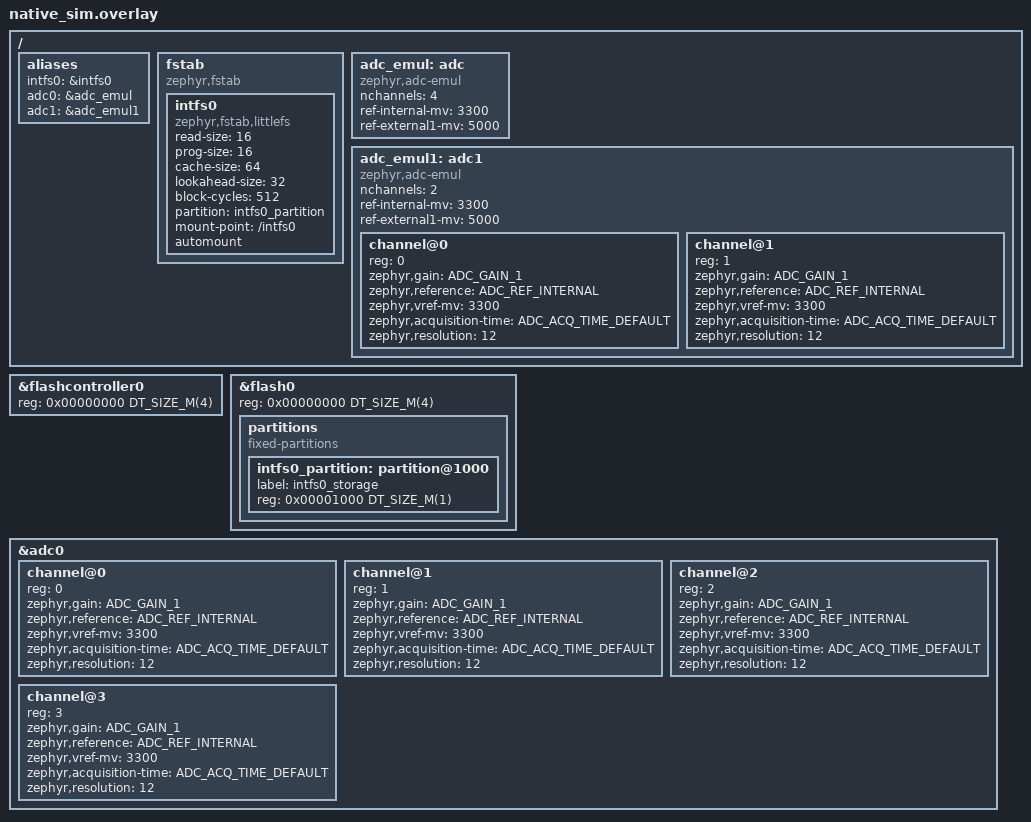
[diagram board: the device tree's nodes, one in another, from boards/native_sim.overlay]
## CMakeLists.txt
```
cmake_minimum_required(VERSION 3.20.0)

set(RT_CORE_TEST_SIM_FLASH ON)
set(RT_CORE_TEST_ADC_EMUL ON)
include(${CMAKE_CURRENT_SOURCE_DIR}/../../../rt_core_test.cmake)

find_package(Zephyr REQUIRED HINTS $ENV{ZEPHYR_BASE})
project(functional_adc_domain)

file(GLOB_RECURSE TEST_SOURCES src/*.c src/*.cpp)

target_sources(app PRIVATE ${TEST_SOURCES})

# With CONFIG_EERIE_LEAP_SMP the test client injects requests with smp_rx_req().
target_include_directories(app PRIVATE
  ${RT_CORE_DIR}/tests/common
  ${ZEPHYR_BASE}/subsys/mgmt/mcumgr/transport/include
)
```

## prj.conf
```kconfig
CONFIG_ZTEST=y

# Language and Compiler
CONFIG_CPP=y
CONFIG_PICOLIBC=y
CONFIG_STD_CPP23=y
CONFIG_REQUIRES_FULL_LIBCPP=y
CONFIG_CPP_EXCEPTIONS=y
CONFIG_CPP_RTTI=y

# Memory
CONFIG_HEAP_MEM_POOL_SIZE=100000

# C++ exception unwinding needs considerably more stack than the ztest defaults.
CONFIG_MAIN_STACK_SIZE=8192
CONFIG_ZTEST_STACK_SIZE=8192

# Logging And Debugging
CONFIG_LOG=y
CONFIG_TEST_RANDOM_GENERATOR=y
CONFIG_THREAD_ANALYZER=y
CONFIG_THREAD_ANALYZER_USE_LOG=y
CONFIG_THREAD_NAME=y
CONFIG_SYS_HEAP_RUNTIME_STATS=y
CONFIG_THREAD_ANALYZER_ISR_STACK_USAGE=n
CONFIG_TIMING_FUNCTIONS=y
CONFIG_CRC=y

# ThreadBase::InitializeStack() falls back to k_thread_stack_alloc().
CONFIG_THREAD_STACK_INFO=y
CONFIG_DYNAMIC_THREAD=y
CONFIG_DYNAMIC_THREAD_ALLOC=y

# FS Config
CONFIG_FLASH=y
CONFIG_FLASH_MAP=y
CONFIG_FILE_SYSTEM=y
CONFIG_FILE_SYSTEM_LITTLEFS=y
CONFIG_FILE_SYSTEM_MKFS=y

CONFIG_ZCBOR=y

# Hardware
CONFIG_ADC=y

CONFIG_EERIE_LEAP_RT_CORE=y
CONFIG_EERIE_LEAP_CONFIGURATION=y
CONFIG_EERIE_LEAP_ADC=y
CONFIG_EERIE_LEAP_DEVICE_TREE=y
CONFIG_EERIE_LEAP_FS=y
CONFIG_EERIE_LEAP_THREADING=y
# The calibration tests stamp their results with the time service.
CONFIG_EERIE_LEAP_TIME=y

CONFIG_EERIE_LEAP_DOMAIN_ADC=y

CONFIG_EERIE_LEAP_CONTROLLER_ADC=y
```

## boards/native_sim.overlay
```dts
/ {
	aliases {
		intfs0 = &intfs0;
		adc0 = &adc_emul;
		adc1 = &adc_emul1;
	};

	fstab {
		compatible = "zephyr,fstab";
		intfs0: intfs0 {
			compatible = "zephyr,fstab,littlefs";
			read-size = <16>;
			prog-size = <16>;
			cache-size = <64>;
			lookahead-size = <32>;
			block-cycles = <512>;
			partition = <&intfs0_partition>;
			mount-point = "/intfs0";
			automount;
		};
	};

	adc_emul: adc {
		compatible = "zephyr,adc-emul";
		nchannels = <4>;
		ref-internal-mv = <3300>;
		ref-external1-mv = <5000>;
		#io-channel-cells = <1>;
		status = "okay";
	};

	adc_emul1: adc1 {
		compatible = "zephyr,adc-emul";
		nchannels = <2>;
		ref-internal-mv = <3300>;
		ref-external1-mv = <5000>;
		#io-channel-cells = <1>;
		status = "okay";
	};
};

&flashcontroller0 {
	reg = <0x00000000 DT_SIZE_M(4)>;  // 4MB flash controller
};

// HEX Flash dump can be found in the duild/flash.bin file
&flash0 {
	reg = <0x00000000 DT_SIZE_M(4)>;  // 4MB total flash

	partitions {
		compatible = "fixed-partitions";
		#address-cells = <1>;
		#size-cells = <1>;

		intfs0_partition: partition@1000 {
			label = "intfs0_storage";
			reg = <0x00001000 DT_SIZE_M(1)>;  // 0x00001000 offset, 1MB size
		};
	};
};

&adc0 {
	#address-cells = <1>;
	#size-cells = <0>;

	channel@0 {
		reg = <0>;
		zephyr,gain = "ADC_GAIN_1";
		zephyr,reference = "ADC_REF_INTERNAL";
		zephyr,vref-mv = <3300>;
		zephyr,acquisition-time = <ADC_ACQ_TIME_DEFAULT>;
		zephyr,resolution = <12>;
	};

	channel@1 {
		reg = <1>;
		zephyr,gain = "ADC_GAIN_1";
		zephyr,reference = "ADC_REF_INTERNAL";
		zephyr,vref-mv = <3300>;
		zephyr,acquisition-time = <ADC_ACQ_TIME_DEFAULT>;
		zephyr,resolution = <12>;
	};

	channel@2 {
		reg = <2>;
		zephyr,gain = "ADC_GAIN_1";
		zephyr,reference = "ADC_REF_INTERNAL";
		zephyr,vref-mv = <3300>;
		zephyr,acquisition-time = <ADC_ACQ_TIME_DEFAULT>;
		zephyr,resolution = <12>;
	};

	channel@3 {
		reg = <3>;
		zephyr,gain = "ADC_GAIN_1";
		zephyr,reference = "ADC_REF_INTERNAL";
		zephyr,vref-mv = <3300>;
		zephyr,acquisition-time = <ADC_ACQ_TIME_DEFAULT>;
		zephyr,resolution = <12>;
	};
};

&adc_emul1 {
	#address-cells = <1>;
	#size-cells = <0>;

	channel@0 {
		reg = <0>;
		zephyr,gain = "ADC_GAIN_1";
		zephyr,reference = "ADC_REF_INTERNAL";
		zephyr,vref-mv = <3300>;
		zephyr,acquisition-time = <ADC_ACQ_TIME_DEFAULT>;
		zephyr,resolution = <12>;
	};

	channel@1 {
		reg = <1>;
		zephyr,gain = "ADC_GAIN_1";
		zephyr,reference = "ADC_REF_INTERNAL";
		zephyr,vref-mv = <3300>;
		zephyr,acquisition-time = <ADC_ACQ_TIME_DEFAULT>;
		zephyr,resolution = <12>;
	};
};
```

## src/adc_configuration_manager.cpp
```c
#include <algorithm>
#include <array>
#include <eerie_memory.hpp>
#include <memory>
#include <string>
#include <vector>
#include <zephyr/kernel.h>
#include <zephyr/ztest.h>

#include "utilities/memory/memory_resource_manager.h"

#include "configuration/cbor/cbor_adc_config/cbor_adc_config.h"
#include "configuration/cbor/cbor_serializer.h"
#include "configuration/services/cbor_configuration_service.h"

#include "subsys/adc/adc_emulator.h"
#include "subsys/adc/adc_manager.h"
#include "subsys/device_tree/dt_adc.h"
#include "subsys/device_tree/dt_fs.h"
#include "subsys/fs/services/fs_service.h"

#include "domain/adc_domain/configuration/adc_configuration_manager.h"
#include "domain/adc_domain/configuration/adc_default_configuration.h"

using namespace eerie_memory;
using namespace eerie_leap::utilities::memory;
using namespace eerie_leap::utilities::voltage_interpolator;
using namespace eerie_leap::configuration::services;
using namespace eerie_leap::subsys::fs::services;
using namespace eerie_leap::subsys::device_tree;
using namespace eerie_leap::subsys::adc;
using namespace eerie_leap::domain::adc_domain::utilities;
using namespace eerie_leap::domain::adc_domain::models;
using namespace eerie_leap::domain::adc_domain::configuration;

namespace {

// The overlay declares two emulated ADCs: four channels, then two.
constexpr int FIRST_ADC_CHANNELS = 4;
constexpr int DT_ADC_COUNT = 2;
constexpr int DT_CHANNEL_COUNT = 6;

std::shared_ptr<FsService> MakeFormattedFsService() {
    DtFs::InitInternalFs();
    auto fs_service = std::make_shared<FsService>(DtFs::GetInternalFsMp());

    fs_service->Format();

    return fs_service;
}

// The first adc_count device-tree ADCs; QEMU targets declare a third one that never initializes.
std::shared_ptr<IAdcManager> MakeAdcManager(int adc_count = DT_ADC_COUNT) {
    DtAdc::Initialize();

    std::vector<std::shared_ptr<IAdc>> adcs;
    adcs.reserve(static_cast<size_t>(adc_count));
    for(int i = 0; i < adc_count; i++)
        adcs.push_back(std::make_shared<AdcEmulator>(DtAdc::Get().value().at(i)));

    auto adc_manager = std::make_shared<AdcManager>(std::move(adcs));
    zassert_true(adc_manager->Initialize());

    return adc_manager;
}

std::shared_ptr<AdcConfigurationManager>
MakeAdcConfigurationManager(std::shared_ptr<FsService> fs_service, std::shared_ptr<IAdcManager> adc_manager) {

    return std::make_shared<AdcConfigurationManager>(
        std::make_unique<CborConfigurationService<CborAdcConfig>>("adc_config", std::move(fs_service)),
        std::move(adc_manager)
    );
}

std::string ExpectedSamplesReason(uint32_t samples) {
    return "Invalid ADC configuration. Samples must be between 1 and "
        + std::to_string(CONFIG_EERIE_LEAP_ADC_SAMPLES_MAX) + ", got " + std::to_string(samples) + ".";
}

void ExpectSameCalibrator(const AdcCalibrator& expected, const AdcCalibrator& actual, size_t channel) {
    zassert_equal(actual.GetInterpolationMethod(), expected.GetInterpolationMethod(), "channel %zu", channel);

    const auto expected_table = expected.GetCalibrationTable();
    const auto actual_table = actual.GetCalibrationTable();
    zassert_equal(actual_table->size(), expected_table->size(), "channel %zu", channel);

    for(size_t j = 0; j < expected_table->size(); j++) {
        zassert_equal(actual_table->at(j).voltage, expected_table->at(j).voltage, "channel %zu point %zu", channel, j);
        zassert_equal(actual_table->at(j).value, expected_table->at(j).value, "channel %zu point %zu", channel, j);
    }
}

} // namespace

ZTEST_SUITE(adc_configuration_manager, NULL, NULL, NULL, NULL, NULL);

static AdcConfiguration AdcConfigurationManagerGetTestConfiguration(int channel_count = DT_CHANNEL_COUNT) {
    const std::pmr::vector<CalibrationData> adc_calibration_data_samples{ { 0.0, 0.0 }, { 5.0, 5.0 } };

    const auto adc_calibration_data_samples_ptr = std::make_shared<std::pmr::vector<CalibrationData>>(
        adc_calibration_data_samples
    );
    const auto adc_calibrator = std::make_shared<AdcCalibrator>(
        InterpolationMethod::LINEAR, adc_calibration_data_samples_ptr
    );

    const auto adc_channel_configuration = std::make_shared<AdcChannelConfiguration>(adc_calibrator);

    std::vector<std::shared_ptr<AdcChannelConfiguration>> channel_configurations;
    channel_configurations.reserve(channel_count);
    for(int i = 0; i < channel_count; i++)
        channel_configurations.push_back(adc_channel_configuration);

    AdcConfiguration adc_configuration;
    adc_configuration.samples = 40;
    adc_configuration.channel_configurations = std::make_shared<std::vector<std::shared_ptr<AdcChannelConfiguration>>>(
        channel_configurations
    );

    return adc_configuration;
}

static void AdcConfigurationManagerExpectTestConfiguration(
    const std::shared_ptr<AdcConfiguration>& configuration,
    int channel_count
) {
    zassert_not_null(configuration.get());
    zassert_equal(configuration->channel_configurations->size(), static_cast<size_t>(channel_count));

    for(int i = 0; i < channel_count; i++) {
        const auto adc_channel_configuration = configuration->channel_configurations->at(i);

        zassert_true(adc_channel_configuration->calibrator != nullptr);
        zassert_equal(adc_channel_configuration->calibrator->GetInterpolationMethod(), InterpolationMethod::LINEAR);

        const auto calibration_table = adc_channel_configuration->calibrator->GetCalibrationTable();
        zassert_equal(calibration_table->size(), 2);
        zassert_equal(calibration_table->at(0).voltage, 0.0F);
        zassert_equal(calibration_table->at(0).value, 0.0F);
        zassert_equal(calibration_table->at(1).voltage, 5.0F);
        zassert_equal(calibration_table->at(1).value, 5.0F);
    }
}

ZTEST(adc_configuration_manager, test_AdcConfigurationManager_Save_config_successfully_saved) {
    const auto fs_service = MakeFormattedFsService();
    const auto adc_manager = MakeAdcManager();
    zassert_equal(adc_manager->GetChannelCount(), DT_CHANNEL_COUNT);

    const auto adc_configuration_manager = MakeAdcConfigurationManager(fs_service, adc_manager);

    const bool result = adc_configuration_manager->Update(AdcConfigurationManagerGetTestConfiguration());
    zassert_true(result);

    const auto saved_configuration = adc_configuration_manager->Get();
    zassert_equal(saved_configuration->samples, 40);
    AdcConfigurationManagerExpectTestConfiguration(saved_configuration, adc_manager->GetChannelCount());
    zassert_equal(adc_configuration_manager->GetAdcManager().get(), adc_manager.get());
}

ZTEST(adc_configuration_manager, test_AdcConfigurationManager_Save_config_and_Load) {
    const auto fs_service = MakeFormattedFsService();
    const auto adc_manager = MakeAdcManager();

    auto adc_configuration_manager = MakeAdcConfigurationManager(fs_service, adc_manager);

    const bool result = adc_configuration_manager->Update(AdcConfigurationManagerGetTestConfiguration());
    zassert_true(result);

    adc_configuration_manager = nullptr;
    adc_configuration_manager = MakeAdcConfigurationManager(fs_service, adc_manager);

    const auto saved_configuration = adc_configuration_manager->Get();
    zassert_equal(saved_configuration->samples, 40);
    AdcConfigurationManagerExpectTestConfiguration(saved_configuration, adc_manager->GetChannelCount());

    // A loaded configuration lives in external RAM, calibration tables included.
    const auto calibration_table =
        saved_configuration->channel_configurations->at(0)->calibrator->GetCalibrationTable();
    zassert_equal(calibration_table->get_allocator().resource(), Mrm::GetExtPmr());
}

ZTEST(adc_configuration_manager, test_AdcConfigurationManager_ApplyCborConfiguration_accepts_an_unordered_table) {
    const auto fs_service = MakeFormattedFsService();
    auto adc_manager = MakeAdcManager();

    const auto adc_configuration_manager = MakeAdcConfigurationManager(fs_service, adc_manager);
    zassert_true(adc_configuration_manager->Update(AdcConfigurationManagerGetTestConfiguration()));

    // The import is stored as received, so the ordering has to come from parsing it.
    eerie_leap::configuration::cbor::CborSerializer<CborAdcConfig> serializer;
    auto exported = adc_configuration_manager->GetCborConfiguration();
    auto cbor_config = serializer.Deserialize(exported);
    zassert_not_null(cbor_config.get());

    for(auto& adc_channel_config : cbor_config->CborAdcChannelConfig_m) {
        adc_channel_config.calibration_table.float32float.back().float32float = 4.0F;
        std::ranges::reverse(adc_channel_config.calibration_table.float32float);
    }

    zassert_true(adc_configuration_manager->ApplyCborConfiguration(serializer.Serialize(*cbor_config)));

    const auto expect_imported_configuration = [&](const std::shared_ptr<AdcConfiguration>& imported_configuration) {
        zassert_not_null(imported_configuration.get());
        zassert_equal(
            imported_configuration->channel_configurations->size(), static_cast<size_t>(adc_manager->GetChannelCount())
        );

        for(int i = 0; i < adc_manager->GetChannelCount(); i++) {
            const auto calibration_table =
                imported_configuration->channel_configurations->at(i)->calibrator->GetCalibrationTable();

            zassert_equal(calibration_table->size(), 2);
            zassert_equal(calibration_table->at(0).voltage, 0.0F);
            zassert_equal(calibration_table->at(1).voltage, 5.0F);
            zassert_equal(calibration_table->at(1).value, 4.0F);
        }
    };

    expect_imported_configuration(adc_configuration_manager->Get());

    const auto reloaded_adc_configuration_manager = MakeAdcConfigurationManager(fs_service, adc_manager);

    expect_imported_configuration(reloaded_adc_configuration_manager->Get());
}

ZTEST(adc_configuration_manager, test_AdcConfigurationManager_ApplyCborConfiguration_reports_why_it_rejects) {
    const auto fs_service = MakeFormattedFsService();
    const auto adc_manager = MakeAdcManager();

    const auto adc_configuration_manager = MakeAdcConfigurationManager(fs_service, adc_manager);

    eerie_leap::configuration::cbor::CborSerializer<CborAdcConfig> serializer;
    const auto exported = adc_configuration_manager->GetCborConfiguration();
    auto cbor_config = serializer.Deserialize(exported);
    zassert_not_null(cbor_config.get());
    cbor_config->samples = 0;

    std::array<char, 96> reason{};
    zassert_false(adc_configuration_manager->ApplyCborConfiguration(serializer.Serialize(*cbor_config), reason));
    zassert_str_equal(reason.data(), ExpectedSamplesReason(0).c_str());
}

ZTEST(
    adc_configuration_manager,
    test_AdcConfigurationManager_ApplyCborConfiguration_rejects_more_channels_than_the_device_tree
) {
    const auto fs_service = MakeFormattedFsService();
    const auto adc_manager = MakeAdcManager();

    const auto adc_configuration_manager = MakeAdcConfigurationManager(fs_service, adc_manager);
    zassert_true(adc_configuration_manager->Update(AdcConfigurationManagerGetTestConfiguration()));

    eerie_leap::configuration::cbor::CborSerializer<CborAdcConfig> serializer;
    auto cbor_config = serializer.Deserialize(adc_configuration_manager->GetCborConfiguration());
    zassert_not_null(cbor_config.get());

    CborAdcChannelConfig extra_channel_config(std::allocator_arg, Mrm::GetDefaultPmr());
    extra_channel_config = cbor_config->CborAdcChannelConfig_m.back();
    cbor_config->CborAdcChannelConfig_m.push_back(std::move(extra_channel_config));
    zassert_equal(cbor_config->CborAdcChannelConfig_m.size(), DT_CHANNEL_COUNT + 1);

    std::array<char, 96> reason{};
    zassert_false(adc_configuration_manager->ApplyCborConfiguration(serializer.Serialize(*cbor_config), reason));
    zassert_str_equal(reason.data(), "Invalid ADC configuration. 7 channels configured, the device tree has 6.");

    // The rejected import neither replaced the configuration nor reached the file.
    AdcConfigurationManagerExpectTestConfiguration(adc_configuration_manager->Get(), DT_CHANNEL_COUNT);
    AdcConfigurationManagerExpectTestConfiguration(adc_configuration_manager->Get(true), DT_CHANNEL_COUNT);
}

ZTEST(adc_configuration_manager, test_AdcConfigurationManager_notifies_after_an_update_not_on_load) {
    const auto fs_service = MakeFormattedFsService();
    const auto adc_manager = MakeAdcManager();

    const auto adc_configuration_manager = MakeAdcConfigurationManager(fs_service, adc_manager);

    int notified = 0;
    adc_configuration_manager->RegisterConfigurationUpdatedHandler([&notified] {
        notified++;
    });

    auto adc_configuration = AdcConfigurationManagerGetTestConfiguration();
    adc_configuration.samples = 10;
    zassert_true(adc_configuration_manager->Update(adc_configuration));
    zassert_equal(notified, 1, "Update() notifies");

    eerie_leap::configuration::cbor::CborSerializer<CborAdcConfig> serializer;
    auto cbor_config = serializer.Deserialize(adc_configuration_manager->GetCborConfiguration());
    zassert_not_null(cbor_config.get());

    cbor_config->samples = 20;
    zassert_true(adc_configuration_manager->ApplyCborConfiguration(serializer.Serialize(*cbor_config)));
    zassert_equal(notified, 2, "ApplyCborConfiguration() notifies once");
    zassert_equal(adc_configuration_manager->Get()->samples, 20);

    cbor_config->samples = 0;
    zassert_false(adc_configuration_manager->ApplyCborConfiguration(serializer.Serialize(*cbor_config)));
    zassert_equal(notified, 2, "a rejected configuration does not notify");

    adc_configuration.samples = 0;
    zassert_false(adc_configuration_manager->Update(adc_configuration));
    zassert_equal(notified, 2, "a rejected update does not notify");

    zassert_not_null(adc_configuration_manager->Get(true).get());
    zassert_equal(notified, 2, "loading does not notify");

    adc_configuration_manager->RegisterConfigurationUpdatedHandler(nullptr);
}

ZTEST(adc_configuration_manager, test_LoadOrCreateDefault_pads_a_stored_configuration_with_fewer_channels) {
    const auto fs_service = MakeFormattedFsService();

    // Stored by firmware that knew only the first ADC.
    const auto first_adc_manager = MakeAdcManager(1);
    zassert_equal(first_adc_manager->GetChannelCount(), FIRST_ADC_CHANNELS);

    auto stored_configuration = AdcConfigurationManagerGetTestConfiguration(FIRST_ADC_CHANNELS);
    stored_configuration.samples = 25;
    {
        const auto adc_configuration_manager = MakeAdcConfigurationManager(fs_service, first_adc_manager);
        zassert_true(adc_configuration_manager->Update(stored_configuration));
    }

    // Loaded by firmware whose device tree adds the second one.
    const auto adc_manager = MakeAdcManager();
    zassert_equal(adc_manager->GetChannelCount(), DT_CHANNEL_COUNT);

    const auto adc_configuration_manager = MakeAdcConfigurationManager(fs_service, adc_manager);
    const auto loaded_configuration = adc_configuration_manager->Get();

    zassert_not_null(loaded_configuration.get());
    zassert_equal(loaded_configuration->samples, 25);
    zassert_equal(loaded_configuration->channel_configurations->size(), DT_CHANNEL_COUNT);

    for(size_t i = 0; i < FIRST_ADC_CHANNELS; i++) {
        ExpectSameCalibrator(
            *stored_configuration.channel_configurations->at(i)->calibrator,
            *loaded_configuration->channel_configurations->at(i)->calibrator, i
        );
    }

    const auto default_calibrator = AdcDefaultConfiguration::CreateCalibrator(Mrm::GetDefaultPmr());
    for(size_t i = FIRST_ADC_CHANNELS; i < DT_CHANNEL_COUNT; i++)
        ExpectSameCalibrator(*default_calibrator, *loaded_configuration->channel_configurations->at(i)->calibrator, i);

    // The user's calibration was loaded, not replaced by a default.
    zassert_false(adc_configuration_manager->IsStoredConfigurationRejected());
    zassert_true(adc_configuration_manager->GetCborConfigurationInfo().is_applied);
}

ZTEST(adc_configuration_manager, test_Default_configuration_matches_the_device_tree) {
    const auto fs_service = MakeFormattedFsService();
    const auto adc_manager = MakeAdcManager();

    const auto adc_configuration_manager = MakeAdcConfigurationManager(fs_service, adc_manager);
    const auto default_configuration = adc_configuration_manager->Get();

    zassert_not_null(default_configuration.get());
    zassert_equal(default_configuration->samples, AdcDefaultConfiguration::SAMPLES);
    zassert_equal(
        default_configuration->channel_configurations->size(), static_cast<size_t>(adc_manager->GetChannelCount())
    );
    zassert_equal(default_configuration->channel_configurations->size(), DT_CHANNEL_COUNT);

    const auto default_calibrator = AdcDefaultConfiguration::CreateCalibrator(Mrm::GetDefaultPmr());
    for(size_t i = 0; i < DT_CHANNEL_COUNT; i++) {
        const auto channel_configuration = default_configuration->channel_configurations->at(i);

        zassert_not_null(channel_configuration.get());
        zassert_not_null(channel_configuration->calibrator.get());
        ExpectSameCalibrator(*default_calibrator, *channel_configuration->calibrator, i);
    }

    // The default was stored, so a reload finds the same configuration rather than creating it again.
    const auto reloaded_configuration = MakeAdcConfigurationManager(fs_service, adc_manager)->Get();
    zassert_equal(reloaded_configuration->samples, AdcDefaultConfiguration::SAMPLES);
    zassert_equal(reloaded_configuration->channel_configurations->size(), DT_CHANNEL_COUNT);
}
```

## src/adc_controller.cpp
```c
#include <algorithm>
#include <memory>
#include <utility>

#include <eerie_memory.hpp>
#include <zephyr/devicetree.h>
#include <zephyr/ztest.h>

#include "utilities/memory/memory_resource_manager.h"

#include "subsys/device_tree/dt_adc.h"
#include "subsys/device_tree/dt_fs.h"
#include "subsys/fs/services/fs_service.h"
#include "subsys/threading/work_queue_thread.h"

#include "domain/adc_domain/configuration/adc_default_configuration.h"
#include "domain/configuration_domain/services/configuration_service.h"

#include "controllers/adc_controller.h"

#include "calibration_test_support.h"

#ifdef CONFIG_EERIE_LEAP_SMP
    #include <zephyr/mgmt/mcumgr/mgmt/mgmt_defines.h>

    #include "domain/adc_domain/smp/calibration_mgmt_group.h"

    #include "smp_test_client.h"
#endif

using eerie_leap::controllers::AdcController;
using eerie_leap::domain::adc_domain::configuration::AdcDefaultConfiguration;
using eerie_leap::domain::configuration_domain::services::ConfigurationService;
using eerie_leap::subsys::device_tree::DtAdc;
using eerie_leap::subsys::device_tree::DtFs;
using eerie_leap::subsys::fs::services::FsService;
using eerie_leap::subsys::threading::WorkQueueThread;
using eerie_leap::utilities::memory::Mrm;

using calibration_test_support::MakeTimeService;
using calibration_test_support::RecordingService;

namespace {

// native_sim declares two emulated ADCs (four channels, then two). QEMU targets declare a third
// one whose channel states no resolution, which rt_core's ADC Initialize() rejects, so there the
// controller must fail to initialize; the smp scenario leaves it out (RT_CORE_TEST_NO_FAILING_ADC).
constexpr bool DT_HAS_FAILING_ADC = DT_NODE_EXISTS(DT_ALIAS(adc2));
constexpr size_t DT_CHANNEL_COUNT = 6;

struct Fixture {
    std::shared_ptr<FsService> fs_service;
    std::shared_ptr<WorkQueueThread> work_queue;
};

Fixture MakeFixture() {
    DtFs::InitInternalFs();
    auto fs_service = std::make_shared<FsService>(DtFs::GetInternalFsMp());
    fs_service->Format();

    DtAdc::Initialize();

    auto work_queue = std::make_shared<WorkQueueThread>("adc_test_config_wq", 6144, 5);
    zassert_true(work_queue->Initialize());

    return { .fs_service = std::move(fs_service), .work_queue = std::move(work_queue) };
}

void ExpectDefaultConfiguration(const AdcController& controller) {
    const auto configuration = controller.GetConfigurationManager()->Get();
    zassert_not_null(configuration.get());
    zassert_equal(configuration->samples, AdcDefaultConfiguration::SAMPLES);
    zassert_equal(configuration->channel_configurations->size(), DT_CHANNEL_COUNT);

    const auto default_calibrator = AdcDefaultConfiguration::CreateCalibrator(Mrm::GetDefaultPmr());
    const auto& default_table = *default_calibrator->GetCalibrationTable();

    for(size_t i = 0; i < DT_CHANNEL_COUNT; i++) {
        const auto& calibrator = configuration->channel_configurations->at(i)->calibrator;
        zassert_not_null(calibrator.get(), "channel %zu", i);
        zassert_equal(
            calibrator->GetInterpolationMethod(), default_calibrator->GetInterpolationMethod(), "channel %zu", i
        );

        const auto& table = *calibrator->GetCalibrationTable();
        zassert_equal(table.size(), default_table.size(), "channel %zu", i);
        for(size_t j = 0; j < table.size(); j++) {
            zassert_equal(table[j].voltage, default_table[j].voltage, "channel %zu point %zu", i, j);
            zassert_equal(table[j].value, default_table[j].value, "channel %zu point %zu", i, j);
        }
    }
}

} // namespace

ZTEST_SUITE(adc_controller, NULL, NULL, NULL, NULL, NULL);

ZTEST(adc_controller, test_Initialize_registers_a_default_configuration_sized_to_the_device_tree) {
    const auto fixture = MakeFixture();
    const auto configuration_service = std::make_shared<ConfigurationService>();

    AdcController controller(fixture.fs_service, fixture.work_queue, configuration_service, nullptr);
    zassert_is_null(controller.GetManager().get());

    if constexpr(DT_HAS_FAILING_ADC) {
        // main() treats this as fatal.
        zassert_equal(controller.Initialize(), -1);
        zassert_is_null(controller.GetManager().get());
        zassert_is_null(controller.GetConfigurationManager().get());
        zassert_false(configuration_service->IsRegistered(ConfigurationService::Type::Adc));
        return;
    }

    zassert_equal(controller.Initialize(), 0);

    zassert_not_null(controller.GetManager().get());
    zassert_equal(controller.GetManager()->GetChannelCount(), static_cast<size_t>(DT_CHANNEL_COUNT));
    zassert_not_null(controller.GetConfigurationManager().get());
    zassert_equal(controller.GetConfigurationManager()->GetAdcManager().get(), controller.GetManager().get());

    ExpectDefaultConfiguration(controller);

    // The configuration service exports what the controller's manager holds.
    zassert_true(configuration_service->IsRegistered(ConfigurationService::Type::Adc));

    const auto exported = configuration_service->GetCborConfiguration(ConfigurationService::Type::Adc);
    const auto expected = controller.GetConfigurationManager()->GetCborConfiguration();
    zassert_false(exported.empty());
    zassert_true(std::ranges::equal(exported, expected));
}

ZTEST(adc_controller, test_Initialize_without_a_configuration_service) {
    const auto fixture = MakeFixture();

    AdcController controller(fixture.fs_service, fixture.work_queue, nullptr, nullptr);

    if constexpr(DT_HAS_FAILING_ADC) {
        zassert_equal(controller.Initialize(), -1);
        zassert_is_null(controller.GetManager().get());
        return;
    }

    zassert_equal(controller.Initialize(), 0);
    zassert_not_null(controller.GetManager().get());
    zassert_is_null(controller.GetCalibrationService().get(), "No calibration without a time service");

    ExpectDefaultConfiguration(controller);
}

// The paused service may be registered before or after Initialize(); a job pauses it either way.
ZTEST(adc_controller, test_Initialize_creates_the_calibration_service) {
    const auto fixture = MakeFixture();

    for(const bool is_registered_first : { true, false }) {
        const auto paused_service = std::make_shared<RecordingService>();

        AdcController controller(fixture.fs_service, fixture.work_queue, nullptr, MakeTimeService());
        zassert_is_null(controller.GetCalibrationService().get());

        if(is_registered_first)
            controller.RegisterPausedService(paused_service);

        if constexpr(DT_HAS_FAILING_ADC) {
            zassert_equal(controller.Initialize(), -1);
            zassert_is_null(controller.GetCalibrationService().get());
            return;
        }

        zassert_equal(controller.Initialize(), 0);

        if(!is_registered_first)
            controller.RegisterPausedService(paused_service);

        const auto calibration_service = controller.GetCalibrationService();
        zassert_not_null(calibration_service.get());

        zassert_false(
            calibration_service->Start(static_cast<int>(DT_CHANNEL_COUNT)), "A channel the unit does not have"
        );
        zassert_true(
            calibration_service->Start(static_cast<int>(DT_CHANNEL_COUNT) - 1), "The last channel, on the second ADC"
        );
        zassert_true(paused_service->IsPaused(), "registered first: %d", is_registered_first);
        zassert_true(calibration_service->Stop());
        zassert_true(paused_service->IsRunning());
        zassert_equal(paused_service->pauses, 1);
        zassert_equal(paused_service->resumes, 1);
    }
}

#ifdef CONFIG_EERIE_LEAP_SMP
namespace {

using eerie_leap::domain::adc_domain::smp::CalibrationMgmtGroup;
using smp_test::CborMap;
using smp_test::Response;
using smp_test::SmpGroupId;
using smp_test::SmpTestClient;

using Command = CalibrationMgmtGroup::Command;
using Error = CalibrationMgmtGroup::Error;

Response Start(SmpTestClient& client, uint32_t channel) {
    return client.Write(
        SmpGroupId::CALIBRATION, std::to_underlying(Command::START), CborMap().Put("channel", channel).Build()
    );
}

Response Stop(SmpTestClient& client) {
    return client.Write(SmpGroupId::CALIBRATION, std::to_underlying(Command::STOP), CborMap().Build());
}

Response Read(SmpTestClient& client) {
    return client.Read(SmpGroupId::CALIBRATION, std::to_underlying(Command::READ));
}

void AssertError(const Response& response, Error error) {
    zassert_equal(response.error_group.value_or(0), std::to_underlying(SmpGroupId::CALIBRATION));
    zassert_equal(
        response.error.value_or(0), std::to_underlying(error), "Expected error %u, got %u", std::to_underlying(error),
        response.error.value_or(0)
    );
}

void AssertNotServed(SmpTestClient& client, const char* message) {
    const auto response = Read(client);
    zassert_false(response.IsOk(), "%s", message);
    zassert_equal(response.Value("rc"), MGMT_ERR_ENOTSUP, "%s", message);
}

} // namespace

// The controller serves calibration over SMP once the service to pause is known, with the unit's
// channel count, and takes the group with it: a second controller registers it again.
ZTEST(adc_controller, test_the_calibration_group_lives_with_the_controller) {
    // The smp scenario leaves the failing ADC out on every board (RT_CORE_TEST_NO_FAILING_ADC); a
    // build that keeps it fails here, so the case cannot go missing as a skip.
    static_assert(!DT_HAS_FAILING_ADC, "the smp scenario must build without the ADC that fails to initialize");

    const auto fixture = MakeFixture();
    SmpTestClient client;

    for(int round = 0; round < 2; round++) {
        const auto paused_service = std::make_shared<RecordingService>();

        {
            AdcController controller(fixture.fs_service, fixture.work_queue, nullptr, MakeTimeService());
            zassert_equal(controller.Initialize(), 0);
            AssertNotServed(client, "Served before the service to pause is known");

            controller.RegisterPausedService(paused_service);
            AssertError(Read(client), Error::NOT_RUNNING);

            AssertError(Start(client, static_cast<uint32_t>(DT_CHANNEL_COUNT)), Error::BAD_CHANNEL);
            zassert_true(Start(client, static_cast<uint32_t>(DT_CHANNEL_COUNT) - 1).IsOk(), "round %d", round);
            zassert_true(controller.GetCalibrationService()->IsRunning());
            zassert_true(paused_service->IsPaused());

            const auto running = Read(client);
            zassert_true(running.IsOk());
            zassert_equal(running.Value("channel"), DT_CHANNEL_COUNT - 1);
            zassert_true(running.Flag("running"));

            zassert_true(Stop(client).IsOk());
            zassert_true(paused_service->IsRunning());
            zassert_equal(paused_service->resumes, 1);
        }

        AssertNotServed(client, "The destroyed controller left its group registered");
    }

    // Registered first, here as a unit with nothing to pause: served from Initialize() on.
    AdcController controller(fixture.fs_service, fixture.work_queue, nullptr, MakeTimeService());
    controller.RegisterPausedService(nullptr);
    zassert_equal(controller.Initialize(), 0);
    AssertError(Read(client), Error::NOT_RUNNING);
    zassert_true(Start(client, 0).IsOk());
    zassert_true(Stop(client).IsOk());
}
#endif
```

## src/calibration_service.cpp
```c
// Calibration samples one channel on its own thread while the service that owns the ADC is paused.
#include <memory>
#include <optional>
#include <vector>

#include <zephyr/drivers/adc/adc_emul.h>
#include <zephyr/kernel.h>
#include <zephyr/ztest.h>

#include "subsys/adc/adc_emulator.h"
#include "subsys/adc/adc_manager.h"
#include "subsys/device_tree/dt_adc.h"

#include "domain/adc_domain/models/adc_range.h"
#include "domain/adc_domain/services/calibration_service.h"

#include "calibration_test_support.h"

using namespace eerie_leap::subsys::adc;
using namespace eerie_leap::subsys::device_tree;
using namespace eerie_leap::domain::adc_domain::models;
using namespace eerie_leap::domain::adc_domain::services;

using namespace calibration_test_support;

ZTEST_SUITE(calibration_service, NULL, NULL, NULL, NULL, NULL);

namespace {

// vref 3300 mV, gain 1, 12 bits on the overlay's first emulated ADC.
constexpr float EMUL_LSB_VOLTS = 3.3F / 4096.0F;
// adc_emul truncates mV × 4095 / 3300 to a whole count, so a constant input lands up to ~1.3 LSB low.
constexpr float EMUL_TOLERANCE = 2.0F * EMUL_LSB_VOLTS;

// The overlay's first emulated ADC, every channel back on a constant so a value function a
// previous test installed is never called.
std::shared_ptr<AdcEmulator> MakeEmulator() {
    DtAdc::Initialize();

    const auto& info = DtAdc::Get().value().at(0);
    for(const auto& channel_config : info.channel_configs)
        zassert_ok(adc_emul_const_value_set(info.adc_device, channel_config.channel_id, 0));

    return std::make_shared<AdcEmulator>(info);
}

std::shared_ptr<AdcManager> MakeAdcManager(std::shared_ptr<IAdc> adc) {
    auto adc_manager = std::make_shared<AdcManager>(std::vector<std::shared_ptr<IAdc>>{ std::move(adc) });
    zassert_true(adc_manager->Initialize());

    return adc_manager;
}

// Pins an emulator channel to a constant input instead of the random stimulus.
void DriveConstant(AdcEmulator& adc, int channel, uint32_t mv) {
    const auto& info = DtAdc::Get().value().at(0);

    adc.SetExternallyDriven(channel);
    zassert_ok(adc_emul_const_value_set(info.adc_device, info.channel_configs.at(channel).channel_id, mv));
}

// Polls until a result newer than @p after_sequence exists.
std::optional<CalibrationService::Result>
WaitForResultAfter(const CalibrationService& service, uint32_t after_sequence) {
    const int64_t end = k_uptime_get() + 10LL * CONFIG_EERIE_LEAP_ADC_CALIBRATION_SAMPLING_RATE_MS;
    while(k_uptime_get() < end) {
        const auto latest = service.GetLatest();
        if(latest.has_value() && latest->sequence > after_sequence)
            return latest;

        k_msleep(5);
    }

    return std::nullopt;
}

} // namespace

ZTEST(calibration_service, test_Start_pauses_and_samples) {
    const auto adc = MakeEmulator();
    const auto adc_manager = MakeAdcManager(adc);
    DriveConstant(*adc, 1, 1500);

    const auto paused_service = std::make_shared<RecordingService>();

    CalibrationService calibration_service(MakeTimeService(), adc_manager, paused_service);
    zassert_true(calibration_service.Initialize());
    zassert_false(calibration_service.GetLatest().has_value());
    zassert_false(calibration_service.IsRunning());
    zassert_false(calibration_service.GetChannel().has_value());

    const AdcStats stats_before = adc->GetStats();

    zassert_true(calibration_service.Start(1));
    zassert_true(calibration_service.IsRunning());
    zassert_equal(calibration_service.GetChannel(), 1);
    zassert_equal(paused_service->pauses, 1);
    zassert_true(paused_service->IsPaused());
    zassert_false(calibration_service.Start(1), "One job at a time");

    const auto first = WaitForResultAfter(calibration_service, 0);
    zassert_true(first.has_value(), "The job produced a result");
    const auto second = WaitForResultAfter(calibration_service, first->sequence);
    zassert_true(second.has_value(), "The job keeps sampling");

    zassert_true(second->sequence > first->sequence);
    zassert_true(second->timestamp > first->timestamp);
    zassert_equal(second->error, AdcError::NONE);
    zassert_within(second->adc_volts, 1.5F, EMUL_TOLERANCE);
    zassert_within(second->sensor_volts, AdcRange::Default().ToSensorVolts(second->adc_volts), 1e-6F);

    zassert_true(calibration_service.Stop());
    zassert_false(calibration_service.IsRunning());
    zassert_equal(calibration_service.GetChannel(), 1, "The latest result still belongs to channel 1");
    zassert_equal(paused_service->resumes, 1);
    zassert_true(paused_service->IsRunning());
    zassert_false(calibration_service.Stop(), "No job left to stop");
    zassert_equal(paused_service->resumes, 1, "Resumed once, by the Stop() that ended the job");

    // Every request was a calibration-sized one, and none follows Stop().
    const AdcStats stats_after = adc->GetStats();
    const uint32_t last_sequence = calibration_service.GetLatest()->sequence;
    const uint32_t requests = stats_after.requests - stats_before.requests;
    zassert_true(requests >= 2);
    zassert_equal(
        stats_after.conversions - stats_before.conversions, requests * CONFIG_EERIE_LEAP_ADC_CALIBRATION_SAMPLES_COUNT
    );

    k_msleep(2 * CONFIG_EERIE_LEAP_ADC_CALIBRATION_SAMPLING_RATE_MS);
    zassert_equal(adc->GetStats().requests, stats_after.requests);
    zassert_equal(calibration_service.GetLatest()->sequence, last_sequence, "The latest result stays readable");
}

ZTEST(calibration_service, test_Start_fails_when_pause_is_refused) {
    const auto adc = MakeEmulator();
    const auto adc_manager = MakeAdcManager(adc);

    // Another owner has it paused or stopped.
    const auto paused_service = std::make_shared<RecordingService>();
    paused_service->is_pause_accepted = false;

    CalibrationService calibration_service(MakeTimeService(), adc_manager, paused_service);
    zassert_true(calibration_service.Initialize());

    const uint32_t requests_before = adc->GetStats().requests;

    zassert_false(calibration_service.Start(1));
    zassert_equal(paused_service->pauses, 1);

    k_msleep(2 * CONFIG_EERIE_LEAP_ADC_CALIBRATION_SAMPLING_RATE_MS);
    zassert_false(calibration_service.GetLatest().has_value(), "Nothing was sampled");
    zassert_equal(adc->GetStats().requests, requests_before);

    zassert_false(calibration_service.Stop());
    zassert_equal(paused_service->resumes, 0, "Nothing it did not pause is resumed");
    zassert_true(paused_service->IsRunning());

    // A later start, once the service can be paused, works.
    paused_service->is_pause_accepted = true;
    zassert_true(calibration_service.Start(1));
    zassert_true(calibration_service.Stop());
    zassert_equal(paused_service->resumes, 1);
}

ZTEST(calibration_service, test_Start_rejects_a_channel_the_unit_does_not_have) {
    const auto adc = MakeEmulator();
    const auto adc_manager = MakeAdcManager(adc);

    const auto paused_service = std::make_shared<RecordingService>();

    CalibrationService calibration_service(MakeTimeService(), adc_manager, paused_service);
    zassert_true(calibration_service.Initialize());

    const uint32_t requests_before = adc->GetStats().requests;

    // The channel is resolved before anything is paused, so a bad one leaves the service running.
    zassert_false(calibration_service.Start(adc_manager->GetChannelCount()));
    zassert_false(calibration_service.Start(-1));
    zassert_equal(paused_service->pauses, 0);
    zassert_true(paused_service->IsRunning());

    k_msleep(2 * CONFIG_EERIE_LEAP_ADC_CALIBRATION_SAMPLING_RATE_MS);
    zassert_false(calibration_service.GetLatest().has_value(), "Nothing was sampled");
    zassert_equal(adc->GetStats().requests, requests_before);
    zassert_false(calibration_service.Stop(), "No job was started");
    zassert_equal(paused_service->resumes, 0);

    // The rejected start left the service usable.
    zassert_true(calibration_service.Start(1));
    zassert_equal(paused_service->pauses, 1);
    zassert_true(calibration_service.Stop());
    zassert_equal(paused_service->resumes, 1);
    zassert_true(paused_service->IsRunning());
}

ZTEST(calibration_service, test_Stop_tolerates_a_resumed_service) {
    const auto adc = MakeEmulator();
    const auto adc_manager = MakeAdcManager(adc);

    const auto paused_service = std::make_shared<RecordingService>();

    CalibrationService calibration_service(MakeTimeService(), adc_manager, paused_service);
    zassert_true(calibration_service.Initialize());

    zassert_true(calibration_service.Start(1));
    zassert_equal(paused_service->pauses, 1);

    // A configuration change restarts the service while the job runs, so it is no longer paused.
    zassert_true(paused_service->Start());
    paused_service->is_resume_accepted = false;

    zassert_true(calibration_service.Stop(), "The job ends although nothing was resumed");
    zassert_false(calibration_service.IsRunning());
    zassert_equal(paused_service->resumes, 1);
    zassert_true(paused_service->IsRunning(), "Left as its owner left it");
    zassert_false(calibration_service.Stop(), "No job left to stop");
    zassert_equal(paused_service->resumes, 1, "The failed resume is not retried");

    // The next job pauses and resumes as usual.
    paused_service->is_resume_accepted = true;
    zassert_true(calibration_service.Start(1));
    zassert_equal(paused_service->pauses, 2);
    zassert_true(calibration_service.Stop());
    zassert_equal(paused_service->resumes, 2);
    zassert_true(paused_service->IsRunning());
}

ZTEST(calibration_service, test_SetServiceToPause_applies_to_the_next_job) {
    const auto adc = MakeEmulator();
    const auto adc_manager = MakeAdcManager(adc);

    const auto first_service = std::make_shared<RecordingService>();
    const auto second_service = std::make_shared<RecordingService>();

    // Constructed before the service it pauses exists, as AdcController may be.
    CalibrationService calibration_service(MakeTimeService(), adc_manager, nullptr);
    zassert_true(calibration_service.Initialize());

    calibration_service.SetServiceToPause(first_service);
    zassert_true(calibration_service.Start(1));
    zassert_true(first_service->IsPaused());

    // A running job still resumes what it paused.
    calibration_service.SetServiceToPause(second_service);
    zassert_true(calibration_service.Stop());
    zassert_equal(first_service->resumes, 1);
    zassert_true(first_service->IsRunning());
    zassert_equal(second_service->pauses, 0);
    zassert_equal(second_service->resumes, 0);

    zassert_true(calibration_service.Start(1));
    zassert_equal(first_service->pauses, 1);
    zassert_equal(second_service->pauses, 1);
    zassert_true(calibration_service.Stop());
    zassert_equal(second_service->resumes, 1);
}

// Start() runs on the MCUmgr work queue, which catches nothing: a pause that throws is a busy one.
ZTEST(calibration_service, test_Start_is_refused_when_pause_throws) {
    const auto adc = MakeEmulator();
    const auto adc_manager = MakeAdcManager(adc);

    const auto paused_service = std::make_shared<RecordingService>();
    paused_service->is_pause_throwing = true;

    CalibrationService calibration_service(MakeTimeService(), adc_manager, paused_service);
    zassert_true(calibration_service.Initialize());

    zassert_false(calibration_service.Start(1));
    zassert_false(calibration_service.IsRunning());
    zassert_equal(paused_service->pauses, 1);
    zassert_false(calibration_service.Stop());
    zassert_equal(paused_service->resumes, 0, "Nothing it did not pause is resumed");

    paused_service->is_pause_throwing = false;
    zassert_true(calibration_service.Start(1));
    zassert_true(calibration_service.Stop());
    zassert_equal(paused_service->resumes, 1);
}

// So does Stop(), also from the destructor: a resume that throws still ends the job.
ZTEST(calibration_service, test_Stop_ends_the_job_when_resume_throws) {
    const auto adc = MakeEmulator();
    const auto adc_manager = MakeAdcManager(adc);

    const auto paused_service = std::make_shared<RecordingService>();

    CalibrationService calibration_service(MakeTimeService(), adc_manager, paused_service);
    zassert_true(calibration_service.Initialize());

    zassert_true(calibration_service.Start(1));
    paused_service->is_resume_throwing = true;

    zassert_true(calibration_service.Stop(), "The job ends although resuming threw");
    zassert_false(calibration_service.IsRunning());
    zassert_equal(paused_service->resumes, 1);
    zassert_false(calibration_service.Stop(), "No job left to stop");
    zassert_equal(paused_service->resumes, 1, "The failed resume is not retried");

    // The next job is not refused for it.
    paused_service->is_resume_throwing = false;
    zassert_true(paused_service->Start());
    zassert_true(calibration_service.Start(1));
    zassert_true(calibration_service.Stop());
    zassert_equal(paused_service->resumes, 2);
    zassert_true(paused_service->IsRunning());
}

// The latest result always belongs to the channel GetChannel() reports.
ZTEST(calibration_service, test_Start_drops_the_previous_jobs_result) {
    const auto adc = MakeEmulator();
    const auto adc_manager = MakeAdcManager(adc);

    CalibrationService calibration_service(MakeTimeService(), adc_manager, nullptr);
    zassert_true(calibration_service.Initialize());

    zassert_true(calibration_service.Start(1));
    zassert_true(WaitForResultAfter(calibration_service, 0).has_value());
    zassert_true(calibration_service.Stop());
    const uint32_t first_job_last = calibration_service.GetLatest()->sequence;

    zassert_true(calibration_service.Start(2));
    zassert_equal(calibration_service.GetChannel(), 2);
    const auto latest = calibration_service.GetLatest();
    zassert_true(
        !latest.has_value() || latest->sequence > first_job_last, "The first job's result %u is reported for channel 2",
        first_job_last
    );

    const auto second_job = WaitForResultAfter(calibration_service, first_job_last);
    zassert_true(second_job.has_value(), "The new job samples");
    zassert_true(calibration_service.Stop());
}
```

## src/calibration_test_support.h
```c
#pragma once

#include <memory>
#include <stdexcept>

#include "subsys/threading/i_service.h"
#include "subsys/time/boot_elapsed_time_provider.h"
#include "subsys/time/rtc_provider.h"
#include "subsys/time/time_service.h"

// Shared by the calibration service and controller suites.
namespace calibration_test_support {

using eerie_leap::subsys::threading::IService;
using eerie_leap::subsys::threading::ServiceState;
using eerie_leap::subsys::time::BootElapsedTimeProvider;
using eerie_leap::subsys::time::RtcProvider;
using eerie_leap::subsys::time::TimeService;

inline std::shared_ptr<TimeService> MakeTimeService() {
    return std::make_shared<TimeService>(std::make_shared<BootElapsedTimeProvider>(), std::make_shared<RtcProvider>());
}

// Stands in for the processing service: running, pausable and resumable unless told otherwise,
// and counting. A throwing pause or resume stands for a reader that cannot be rebuilt.
class RecordingService : public IService {
private:
    ServiceState state_ = ServiceState::RUNNING;

public:
    bool is_pause_accepted = true;
    bool is_resume_accepted = true;
    bool is_pause_throwing = false;
    bool is_resume_throwing = false;
    int pauses = 0;
    int resumes = 0;

    bool Initialize() override {
        return true;
    }
    bool Start() override {
        state_ = ServiceState::RUNNING;
        return true;
    }
    bool Stop() override {
        state_ = ServiceState::STOPPED;
        return true;
    }

    bool Pause() override {
        pauses++;
        if(is_pause_throwing)
            throw std::runtime_error("pause failed");

        if(!is_pause_accepted)
            return false;

        state_ = ServiceState::PAUSED;
        return true;
    }

    bool Resume() override {
        resumes++;
        if(is_resume_throwing)
            throw std::runtime_error("resume failed");

        if(!is_resume_accepted)
            return false;

        state_ = ServiceState::RUNNING;
        return true;
    }

    [[nodiscard]] bool IsPausable() const noexcept override {
        return true;
    }
    [[nodiscard]] ServiceState GetState() const noexcept override {
        return state_;
    }
};

} // namespace calibration_test_support
```
